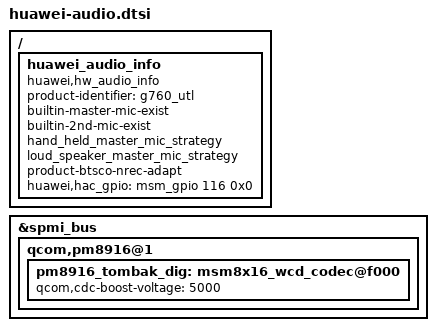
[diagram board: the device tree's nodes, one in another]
/* < DTS201505289999M zhujie 20150528 begin */
/ {
    huawei_audio_info {
        compatible = "huawei,hw_audio_info";
        product-identifier = "g760_utl";
        builtin-master-mic-exist;
        builtin-2nd-mic-exist;
        hand_held_master_mic_strategy;
        status = "ok";
        loud_speaker_master_mic_strategy;
        product-btsco-nrec-adapt;
        huawei,hac_gpio = <&msm_gpio 116 0x0>;
    };
};
&spmi_bus {
        qcom,pm8916@1 {
                pm8916_tombak_dig: msm8x16_wcd_codec@f000{
                        qcom,cdc-boost-voltage = <5000>;
                };
        };
};
/* DTS201505289999M zhujie 20150528 end > */
